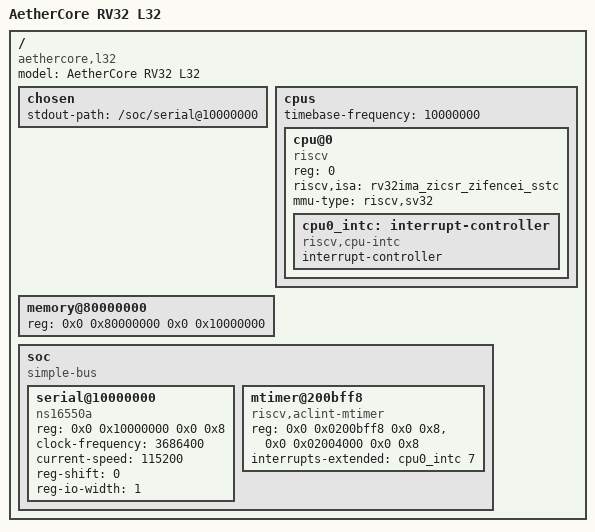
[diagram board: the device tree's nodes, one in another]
/dts-v1/;

/ {
    #address-cells = <2>;
    #size-cells = <2>;
    compatible = "aethercore,l32";
    model = "AetherCore RV32 L32";

    chosen {
        stdout-path = "/soc/serial@10000000";
    };

    cpus {
        #address-cells = <1>;
        #size-cells = <0>;
        timebase-frequency = <10000000>;

        cpu@0 {
            device_type = "cpu";
            reg = <0>;
            status = "okay";
            compatible = "riscv";
            riscv,isa = "rv32ima_zicsr_zifencei_sstc";
            mmu-type = "riscv,sv32";

            cpu0_intc: interrupt-controller {
                #interrupt-cells = <1>;
                interrupt-controller;
                compatible = "riscv,cpu-intc";
            };
        };
    };

    memory@80000000 {
        device_type = "memory";
        reg = <0x0 0x80000000 0x0 0x10000000>;
    };

    soc {
        #address-cells = <2>;
        #size-cells = <2>;
        compatible = "simple-bus";
        ranges;

        serial@10000000 {
            compatible = "ns16550a";
            reg = <0x0 0x10000000 0x0 0x8>;
            clock-frequency = <3686400>;
            current-speed = <115200>;
            reg-shift = <0>;
            reg-io-width = <1>;
            status = "okay";
        };

        mtimer@200bff8 {
            compatible = "riscv,aclint-mtimer";
            reg = <0x0 0x0200bff8 0x0 0x8>,
                  <0x0 0x02004000 0x0 0x8>;
            reg-names = "mtime", "mtimecmp";
            interrupts-extended = <&cpu0_intc 7>;
        };
    };
};
